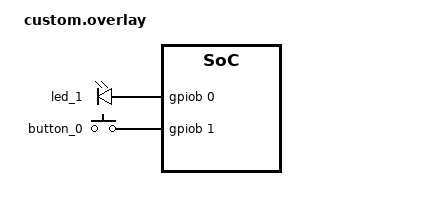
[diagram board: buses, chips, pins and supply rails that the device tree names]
#include <zephyr/dt-bindings/input/input-event-codes.h>

/ {
    leds {
        compatible = "gpio-leds";
        led_1: led_1 {
            gpios = <&gpiob 0 GPIO_ACTIVE_HIGH>;
        };
    };

    buttons {
        compatible = "gpio-keys";
        button_0: button_0 {
            gpios = <&gpiob 1 GPIO_ACTIVE_HIGH>;
            zephyr,code = <INPUT_KEY_0>;
        };
    };

    aliases {
        led1 = &led_1;
        button0 = &button_0;
    };
};

